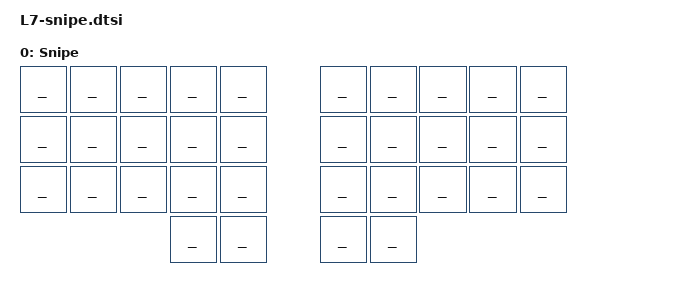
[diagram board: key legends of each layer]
/**
 * Held with the / key on the Mouse layer. Every key falls through to the Mouse layer; while this
 * layer is on, the pointer input listener in sweep.keymap forces speed level 1.
 */

/ {
  keymap {
    compatible = "zmk,keymap";

	snipe_layer {
		label = "Snipe";
		bindings = <
//	╭───────────────┬───────────────┬───────────────┬───────────────┬───────────────╮   ╭───────────────┬───────────────┬───────────────┬───────────────┬───────────────╮
	________		________    	________		________		________			________        ________     	________        ________        ________
//	├───────────────┼───────────────┼───────────────┼───────────────┼───────────────┤   ├───────────────├───────────────┼───────────────┼───────────────┼───────────────┤
	________		________    	________		________		________			________        ________     	________        ________        ________
//	├───────────────┼───────────────┼───────────────┼───────────────┼───────────────┤   ├───────────────├───────────────┼───────────────┼───────────────┼───────────────┤
	________		________        ________        ________		________            ________        ________     	________        ________        ________
//	╰───────────────┴───────────────┼───────────────┼───────────────┼───────────────┤   ├───────────────├───────────────┼───────────────┼───────────────┴───────────────╯
	       											________        ________           	________		________
//                                                  ╰───────────────┴───────────────╯   ╰───────────────┴───────────────╯
			>;
		};
	};
};
